# ADuCM302x register map
Vendor: Analog Devices; Series: ADuCM302x; File version: 1p0
CPU: CM3 r0p1, little endian, no MPU, no FPU, 3 interrupt priority bits
Registers are 32-bit, read-write, reset 0x0 unless marked. A register's access mark holds for its fields unless they carry their own. Offsets are from the block's base; [hi:lo] are bit positions; {n}, {i} and the like mark numbered series.

## CRYPT0 — Register Map for the Crypto Block
Base 0x40044000
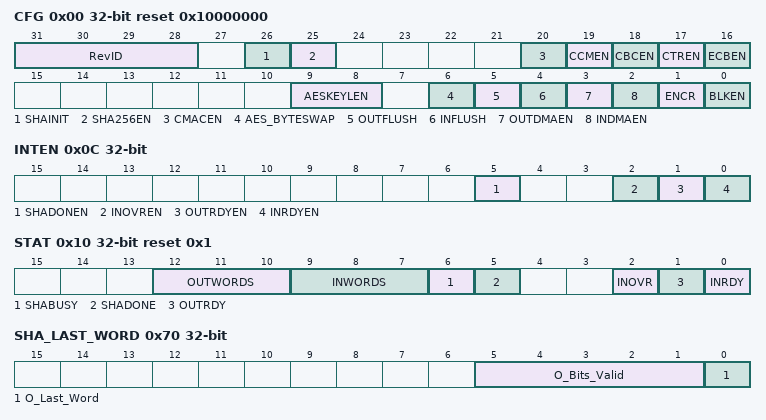
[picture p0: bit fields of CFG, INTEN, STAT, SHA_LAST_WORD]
0x00 CFG reset 0x10000000 — Configuration Register
  [31:28] RevID ro — Rev ID for Crypto
  [26] SHAINIT range 0x00000000..0x00000001 — Restarts SHA Computation
  [25] SHA256EN range 0x00000000..0x00000001 — Enable SHA-256 Operation
  [20] CMACEN range 0x00000000..0x00000001 — Enable CMAC Mode Operation
  [19] CCMEN range 0x00000000..0x00000001 — Enable CCM/CCM* Mode Operation
  [18] CBCEN range 0x00000000..0x00000001 — Enable CBC Mode Operation
  [17] CTREN range 0x00000000..0x00000001 — Enable CTR Mode Operation
  [16] ECBEN range 0x00000000..0x00000001 — Enable ECB Mode Operation
  [9:8] AESKEYLEN — Select Key Length for AES Cipher
    0=Uses 128-bit long key; 2=Uses 256-bit long key
  [6] AES_BYTESWAP range 0x00000000..0x00000001 — Byte Swap 32 Bit AES Input Data
  [5] OUTFLUSH wo range 0x00000000..0x00000001 — Output Buffer Flush
  [4] INFLUSH wo range 0x00000000..0x00000001 — Input Buffer Flush
  [3] OUTDMAEN — Enable DMA Channel Request for Output Buffer
    0=DMA_DISABLE_OUTBUF (Disable DMA Requesting for Output Buffer); 1=DMA_ENABLE_OUTBUF (Enable DMA Requesting for Output Buffer)
  [2] INDMAEN — Enable DMA Channel Request for Input Buffer
    0=DMA_DISABLE_INBUF (Disable DMA Requesting for Input Buffer); 1=DMA_ENABLE_INBUF (Enable DMA Requesting for Input Buffer)
  [1] ENCR — Encrypt or Decrypt
  [0] BLKEN — Enable Bit for Crypto Block
    0=Enable Crypto Block; 1=Disable Crypto Block
0x04 DATALEN — Payload Data Length
  [19:0] VALUE range 0x00000000..0x000FFFFF — Length of Payload Data
0x08 PREFIXLEN — Authentication Data Length
  [15:0] VALUE range 0x00000000..0x0000FFFF — Length of Associated Data
0x0C INTEN — Interrupt Enable Register
  [5] SHADONEN range 0x00000000..0x00000001 — Enable SHA_Done Interrupt
  [2] INOVREN range 0x00000000..0x00000001 — Enable Input Overflow Interrupt
  [1] OUTRDYEN range 0x00000000..0x00000001 — Enables the Output Ready Interrupt
  [0] INRDYEN range 0x00000000..0x00000001 — Enable Input Ready Interrupt
0x10 STAT reset 0x1 — Status Register
  [12:10] OUTWORDS ro — Number of Words in the Output Buffer
  [9:7] INWORDS ro — Number of Words in the Input Buffer
  [6] SHABUSY ro — SHA Busy. in Computation
  [5] SHADONE ro — SHA Computation complete
  [2] INOVR range 0x00000000..0x00000001 — Overflow in the Input Buffer
  [1] OUTRDY ro — Output Data Ready
  [0] INRDY ro — Input Buffer Status
0x14 INBUF — Input Buffer
  [31:0] VALUE wo range 0x00000000..0xFFFFFFFF
0x18 OUTBUF — Output Buffer
  [31:0] VALUE ro
{0x1C+4i} NONCE{i} (i=0..3) — Nonce Bits [{32i+31}:{32i}]
  [31:0] VALUE range 0x00000000..0xFFFFFFFF — Word {i}: Nonce Bits [{32i+31}:{32i}]
{0x2C+4i} AESKEY{i} (i=0..7) — AES Key Bits [{32i+31}:{32i}]
  [31:0] VALUE wo range 0x00000000..0xFFFFFFFF — Key: Bytes [{4i+3}:{4i}]
0x4C CNTRINIT — Counter Initialization Vector
  [19:0] VALUE range 0x00000000..0x000FFFFF — Counter Initialization Value
0x50 SHAH0 reset 0x6A09E667 — SHA Bits [31:0]
  [31:0] SHAHASH0 range 0x00000000..0xFFFFFFFF — Word 0: SHA Hash
0x54 SHAH1 reset 0xBB67AE85 — SHA Bits [63:32]
  [31:0] SHAHASH1 range 0x00000000..0xFFFFFFFF — Word 1: SHA Hash
0x58 SHAH2 reset 0x3C6EF372 — SHA Bits [95:64]
  [31:0] SHAHASH2 range 0x00000000..0xFFFFFFFF — Word 2: SHA Hash
0x5C SHAH3 reset 0xA54FF53A — SHA Bits [127:96]
  [31:0] SHAHASH3 range 0x00000000..0xFFFFFFFF — Word 3: SHA Hash
0x60 SHAH4 reset 0x510E527F — SHA Bits [159:128]
  [31:0] SHAHASH4 range 0x00000000..0xFFFFFFFF — Word 4: SHA Hash
0x64 SHAH5 reset 0x9B05688C — SHA Bits [191:160]
  [31:0] SHAHASH5 range 0x00000000..0xFFFFFFFF — Word 5: SHA Hash
0x68 SHAH6 reset 0x1F83D9AB — SHA Bits [223:192]
  [31:0] SHAHASH6 range 0x00000000..0xFFFFFFFF — Word 6: SHA Hash
0x6C SHAH7 reset 0x5BE0CD19 — SHA Bits [255:224]
  [31:0] SHAHASH7 range 0x00000000..0xFFFFFFFF — Word 7: SHA Hash
0x70 SHA_LAST_WORD — SHA Last Word and Valid Bits Information
  [5:1] O_Bits_Valid range 0x00000000..0x0000001F — Bits Valid in SHA Last Word Input
  [0] O_Last_Word range 0x00000000..0x00000001 — Last SHA Input Word
0x74 CCM_NUM_VALID_BYTES — NUM_VALID_BYTES
  [3:0] NUM_VALID_BYTES range 0x00000000..0x0000000F — Number of Valid Bytes in CCM Last Data
